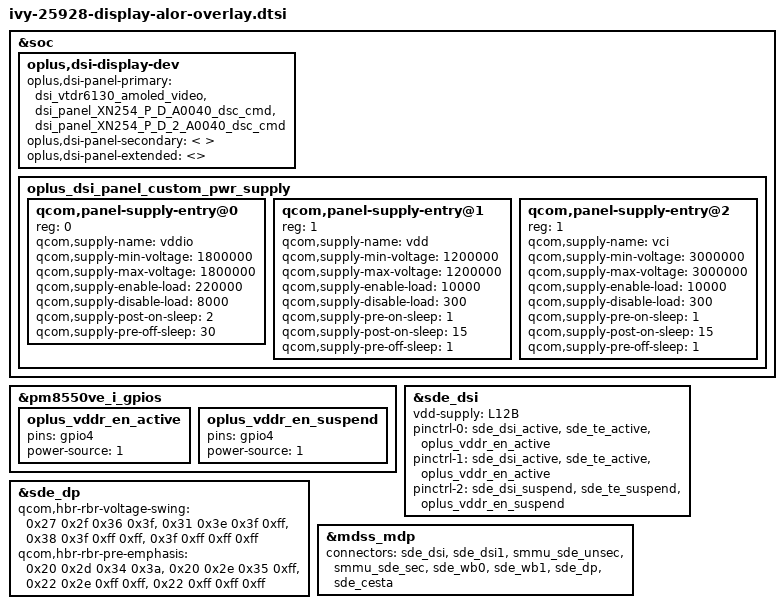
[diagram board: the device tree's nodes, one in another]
#include "panel/dsi-panel-XN254-P-D-A0040-dsc-cmd.dtsi"
#include "panel/dsi-panel-XN254-P-D-2-A0040-dsc-cmd.dtsi"

&soc {
	oplus,dsi-display-dev {
		oplus,dsi-panel-primary = <
			&dsi_vtdr6130_amoled_video
			&dsi_panel_XN254_P_D_A0040_dsc_cmd
			&dsi_panel_XN254_P_D_2_A0040_dsc_cmd
		>;
		oplus,dsi-panel-secondary = <
		>;
		oplus,dsi-panel-extended = <>;
	};

	oplus_dsi_panel_custom_pwr_supply: oplus_dsi_panel_custom_pwr_supply {
		#address-cells = <1>;
		#size-cells = <0>;

		qcom,panel-supply-entry@0 {
			reg = <0>;
			qcom,supply-name = "vddio";
			qcom,supply-min-voltage = <1800000>;
			qcom,supply-max-voltage = <1800000>;
			qcom,supply-enable-load = <220000>;
			qcom,supply-disable-load = <8000>;
			qcom,supply-post-on-sleep = <2>;
			qcom,supply-pre-off-sleep = <30>;
		};

		qcom,panel-supply-entry@1 {
			reg = <1>;
			qcom,supply-name = "vdd";
			qcom,supply-min-voltage = <1200000>;
			qcom,supply-max-voltage = <1200000>;
			qcom,supply-enable-load = <10000>;
			qcom,supply-disable-load = <300>;
			qcom,supply-pre-on-sleep = <1>;
			qcom,supply-post-on-sleep = <15>;
			qcom,supply-pre-off-sleep = <1>;
		};

		qcom,panel-supply-entry@2 {
			reg = <1>;
			qcom,supply-name = "vci";
			qcom,supply-min-voltage = <3000000>;
			qcom,supply-max-voltage = <3000000>;
			qcom,supply-enable-load = <10000>;
			qcom,supply-disable-load = <300>;
			qcom,supply-pre-on-sleep = <1>;
			qcom,supply-post-on-sleep = <15>;
			qcom,supply-pre-off-sleep = <1>;
		};
	};
};

&pm8550ve_i_gpios {
	oplus_vddr_en_active: oplus_vddr_en_active {
		pins = "gpio4";
		power-source = <1>; /* 1.8V */

	};

	oplus_vddr_en_suspend: oplus_vddr_en_suspend  {
		pins = "gpio4";
		power-source = <1>; /* 1.8V */

	};
};

&sde_dsi {
	vdd-supply = <&L12B>;
	pinctrl-names = "panel_active", "panel_active_with_esync", "panel_suspend";
	pinctrl-0 = <&sde_dsi_active &sde_te_active &oplus_vddr_en_active>;
	pinctrl-1 = <&sde_dsi_active &sde_te_active &oplus_vddr_en_active>;
	pinctrl-2 = <&sde_dsi_suspend &sde_te_suspend &oplus_vddr_en_suspend>;
};

&sde_dp {
	status = "ok";
};

&mdss_mdp {
	connectors = <&sde_dsi &sde_dsi1 &smmu_sde_unsec &smmu_sde_sec
			&sde_wb0 &sde_wb1 &sde_dp &sde_cesta>;
};

&sde_dp {
		qcom,hbr-rbr-voltage-swing = <0x27 0x2f 0x36 0x3f>,
					<0x31 0x3e 0x3f 0xff>,
					<0x38 0x3f 0xff 0xff>,
					<0x3f 0xff 0xff 0xff>;
		qcom,hbr-rbr-pre-emphasis = <0x20 0x2d 0x34 0x3a>,
					<0x20 0x2e 0x35 0xff>,
					<0x22 0x2e 0xff 0xff>,
					<0x22 0xff 0xff 0xff>;
};
